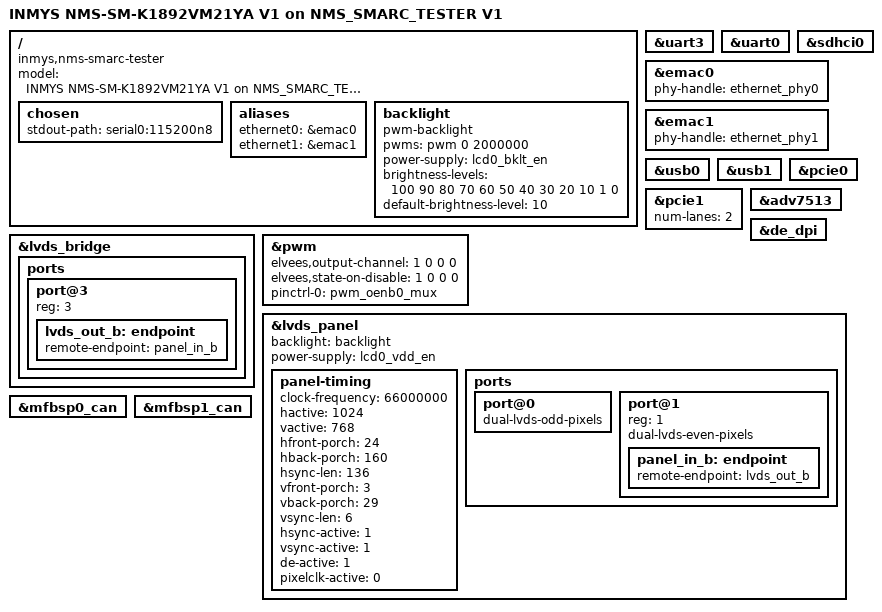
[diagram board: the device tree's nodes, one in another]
// SPDX-License-Identifier: GPL-2.0+
/*
 * NMS_SMARC_TESTER V1 - SMARC test/burn-in carrier
 *
 * The tester is a multi-purpose bring-up board (Ethernet, HDMI/DP,
 * LVDS/eDP converter, M.2 SATA/WiFi, USB, CAN, SD, FPGA GPIO...).
 * Only the resources needed for bring-up are described here; the
 * remaining peripherals are added as they are validated.
 *
 * Copyright (C) 2026 INMYS
 */

/dts-v1/;

#include <dt-bindings/gpio/gpio.h>
#include <dt-bindings/pwm/pwm.h>

#include "nms-sm-k1892vm21ya.dtsi"

/ {
	model = "INMYS NMS-SM-K1892VM21YA V1 on NMS_SMARC_TESTER V1";
	compatible = "inmys,nms-smarc-tester",
		     "inmys,nms-sm-k1892vm21ya",
		     "inmys,nms-sm-k1892",
		     "elvees,mcom03r";

	chosen {
		stdout-path = "serial0:115200n8";
	};

	aliases {
		ethernet0 = &emac0;
		ethernet1 = &emac1;
	};

	/*
	 * No panel is fitted on the tester; the LVDS pairs go to the
	 * converter/receivers.  The node exists so that the SN65DSI84 has a
	 * sink and a mode to drive, which is what the LVDS part of the test
	 * needs - 800x480 at 33 MHz keeps the bit rate at 7 x 33 = 231 Mbit/s
	 * per lane pair.  The timing is the one in the module device tree.
	 */
	backlight: backlight {
		compatible = "pwm-backlight";
		pwms = <&pwm 0 2000000>; /* 500 Hz, port 0 output B */
		power-supply = <&lcd0_bklt_en>;
		brightness-levels = <100 90 80 70 60 50 40 30 20 10 1 0>;
		default-brightness-level = <10>;
	};
};

/* SER0 console (RS-232/USB-UART on the tester) */
&uart3 {
	status = "okay";
};

&uart0 {
	status = "okay";
};

/* microSD / SDIO socket on the tester */
&sdhci0 {
	status = "okay";
};

/* Ethernet (1000BASE-T magnetics + RJ45) */
&emac0 {
	status = "okay";
	phy-handle = <&ethernet_phy0>;
};

&emac1 {
	status = "okay";
	phy-handle = <&ethernet_phy1>;
};

/* USB host ports (module hub) and USB-SATA bridge */
&usb0 {
	status = "okay";
};

&usb1 {
	status = "okay";
};

/*
 * PCIe slot / M.2.  No reset-gpio: the controller drives the
 * PCIx_PERSTN pad itself, and the driver only falls back to that when the
 * property is absent.  The previous `reset-gpios = <&gpio0b 4 ...>` was
 * doubly wrong - the driver looks for "reset-gpio" (singular), and
 * GPIO0_PORTB_4 is ball BB34 = WDT_TIME_OUT# on SMARC S145, not a PCIe
 * reset at all.
 */
&pcie0 {
	status = "okay";
};

/*
 * PCI1 is safe to enable here and nowhere else: its reference clock is gated
 * by PCIE_B_CLKREQ#, so it only runs while a card sits in SMARC PCIe B.  This
 * carrier has cards in A, B and C, so the clock is present.  See the comment
 * on &pcie1 in nms-sm-k1892vm21ya.dtsi for the full story.
 *
 * Only two lanes are wired to PCI1 (PCI1x2.0/1) and they reach slots C and D
 * through the D25/D26 2:1 muxes, which is why num-lanes is 2 and not 4.
 *
 * The mux select, PCIE_SEL (PCAL6416A P0_6), is left at its default of 0,
 * which routes PCI1 to C/D.  Setting it to 1 hands C/D back to PCI0 lanes 2/3
 * and leaves PCI1 with nothing to talk to.
 */
&pcie1 {
	status = "okay";
	num-lanes = <2>;
};

/* HDMI/DP test path */
&adv7513 {
	status = "okay";
};

&de_dpi {
	status = "okay";
};

/*
 * LVDS test path: Mali-DP -> DSI -> SN65DSI84 -> SMARC LVDS0 + LVDS1.  The
 * panel power and backlight enables are the standard SMARC LCD0_VDD_EN
 * (S133) and LCD0_BKLT_EN (S127) lines; the tester schematic has not been
 * checked pin by pin, so if the converter is powered from a fixed rail
 * instead, drop the two power-supply properties.
 *
 * The link is dual on this carrier.  The module wires both SN65DSI84
 * channels to the connector - A to LVDS0 (S125..S138), B to LVDS1
 * (S108..S121) - and the tester has a FIN1032 receiver on every pair of
 * both, feeding the FPGA:
 *
 *   channel A  CLK S134/S135 -> D32   Y0 S125/S126 -> D30
 *              Y1  S128/S129 -> D30   Y2 S131/S132 -> D32
 *              Y3  S137/S138 -> D32
 *   channel B  CLK S108/S109 -> D31   Y0 S120/S121 -> D30
 *              Y1  S111/S112 -> D31   Y2 S117/S118 -> D31
 *              Y3  S114/S115 -> D31
 *
 * A single link leaves channel B silent, so dual is the only way to prove
 * that B reaches the far end at all.  It is also why this stays here and
 * not in the module dtsi: the 7" panel the other carriers drive is a
 * single-link part and would get half a picture per channel.
 */
&lvds_bridge {
	status = "okay";

	ports {
		/* LVDS channel B -> panel port 1 */
		port@3 {
			reg = <3>;
			lvds_out_b: endpoint {
				remote-endpoint = <&panel_in_b>;
			};
		};
	};
};

/*
 * Backlight PWM.  SMARC LCD0_BKLT_PWM (S141) is D2.AW17 = GPIO1_PORTD_3,
 * whose alternate function is PWM_OENB0 - port 0 output B of the
 * elvees-pwm block at 0x1770000 - so elvees,output-channel[0] = 1 selects
 * the B output.  The designware timers cannot reach this pin; see the
 * module device tree.
 */
&pwm {
	status = "okay";
	elvees,output-channel = <1 0 0 0>;
	elvees,state-on-disable = <1 0 0 0>;
	pinctrl-names = "default";
	pinctrl-0 = <&pwm_oenb0_mux>;
};

/*
 * The bridge works out dual link from drm_of_lvds_get_dual_link_pixel_order()
 * over its port@2 and port@3, which reads the markers on the panel's port
 * nodes: one has to say dual-lvds-odd-pixels and the other
 * dual-lvds-even-pixels.  Channel A carries the odd pixels, the arrangement
 * the freescale dual-link panels use.
 *
 * Nothing here is a real panel - the "panel" is the tester's FPGA - so the
 * timings stay the module's 800x480 at 33 MHz and the bridge halves them
 * itself: each channel then carries 400 pixels per line at 16.5 MHz.
 */
&lvds_panel {
	status = "okay";
	backlight = <&backlight>;
	power-supply = <&lcd0_vdd_en>;

	/*
	 * A different mode than the module's 7" panel, and only because a dual
	 * link halves the LVDS clock: the SN65DSI84's LVDS_CLK_RANGE starts at
	 * 25 MHz, so 800x480 at 33 MHz would ask for 16.5 MHz per channel,
	 * below what the part can generate.  The bridge then never settles -
	 * it latches PLL_UNLOCK and CHA_SYNCH_ERR, the driver resets the pipe
	 * in a loop, and the frame comes out as a single line.
	 *
	 * 1024x768 at 66 MHz gives 33.3 MHz per channel, inside the
	 * 25..37.5 MHz range.  The pixel clock is not free to be chosen
	 * either: disp_pxlclk is media_pll1 (594 MHz) over an integer UCG
	 * divider, so only 594/N exists - 148.5, 118.8, 99, 74.25, 66, 59.4,
	 * 54, 49.5, 33 - and mcom03_dsi_mode_valid() demands an exact match.
	 * 65 MHz, the obvious choice, is simply not producible and the mode
	 * gets rejected with an empty crtc.
	 *
	 *   DSI clock     = 66 * 24 bpp / 4 lanes / 2 = 198 MHz
	 *   DSI_CLK_RANGE = 198 / 5 = 39.6 -> 40, so the bridge runs 200 MHz
	 *   LVDS divider  = 24 / 4 - 1 = 5, so 200 / 6 = 33.3 MHz
	 *
	 * The 1% the 5 MHz DSI grid adds is the same one the single-link mode
	 * has (see HARDWARE.md); it only lengthens the blanking.  The tester's
	 * FPGA measures whatever it is given and nothing here is a real panel,
	 * so the mode is free to be chosen for the bridge, not for a display.
	 */
	panel-timing {
		clock-frequency = <66000000>;
		hactive = <1024>;
		vactive = <768>;
		hfront-porch = <24>;
		hback-porch = <160>;
		hsync-len = <136>;
		vfront-porch = <3>;
		vback-porch = <29>;
		vsync-len = <6>;
		hsync-active = <1>;
		vsync-active = <1>;
		de-active = <1>;
		pixelclk-active = <0>;
	};

	ports {
		port@0 {
			dual-lvds-odd-pixels;
		};

		port@1 {
			reg = <1>;
			dual-lvds-even-pixels;

			panel_in_b: endpoint {
				remote-endpoint = <&lvds_out_b>;
			};
		};
	};
};

/* CAN bus connectors */
&mfbsp0_can {
	status = "okay";
};

&mfbsp1_can {
	status = "okay";
};
